# STM32N645 register map
File version: 1.0
CPU: CM55 r0p1, little endian, no MPU, FPU, vendor SysTick, 8 interrupt priority bits
Registers are 32-bit, read-write, reset 0x0 unless marked. A register's access mark holds for its fields unless they carry their own. Offsets are from the block's base; [hi:lo] are bit positions; {n}, {i} and the like mark numbered series.

## PWR — Power control
Base 0x46024800
Same registers: PWR_S 0x56024800
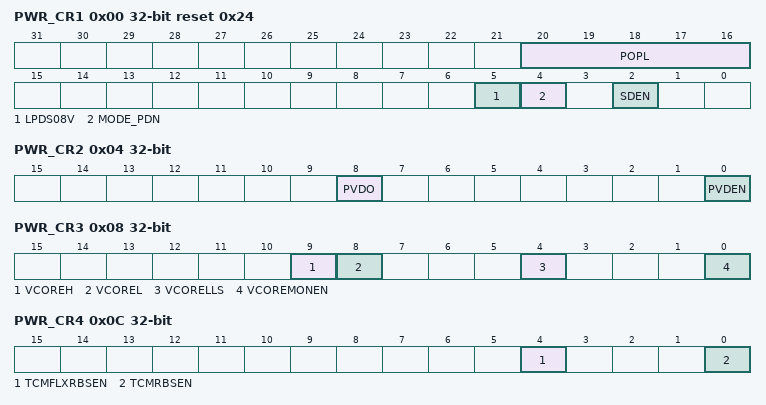
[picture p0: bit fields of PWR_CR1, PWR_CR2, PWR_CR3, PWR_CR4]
0x00 PWR_CR1 access per field reset 0x24 — PWR control register 1
  [20:16] POPL rw — pwr_on pulse low configuration.
    0=No guaranteed minimum low time; 1=~ 1 ms guaranteed minimum low time (1 x 32 LSI cycles); 2=~ 2 ms guaranteed minimum low time (2 x 32 LSI cycles); 31=~ 31 ms guaranteed minimum low time (31 x 32 LSI cycles)
  [5] LPDS08V rw — SMPS low-power mode enable (SVOS high only)
    0=SMPS low-power mode disabled; 1=SMPS low-power mode enabled (high-efficiency mode) (default)
  [4] MODE_PDN rw — Enables the pull down on output voltage during power-down mode
    0=Pull-down disabled. The output is in high impedance during the shutdown (default).; 1=Pull-down enabled
  [2] SDEN rw-once — SMPS step-down converter enable
    0=SMPS step-down converter disabled; 1=SMPS step-down converter enabled (default)
0x04 PWR_CR2 access per field — PWR control register 2
  [8] PVDO ro — Programmable voltage detect output
    0=Voltage level on PVD_IN is equal or higher than the internal VREFINT; 1=Voltage level on PVD_IN is lower than the internal VREFINT
  [0] PVDEN rw — Programmable voltage detector enable
    0=PVD disabled; 1=PVD enabled
0x08 PWR_CR3 access per field — PWR control register 3
  [9] VCOREH ro — Monitored V less than sub>DDCORE less than /sub> level above high threshold
    0=V less than sub>DDCORE less than /sub> level below high threshold level, or monitor disabled; 1=V less than sub>DDCORE less than /sub> level equal or above high threshold level
  [8] VCOREL ro — Monitored V less than sub>DDCORE less than /sub> level above low threshold
    0=V less than sub>DDCORE less than /sub> level above low threshold level, or monitor disabled; 1=V less than sub>DDCORE less than /sub> level equal or below low threshold level
  [4] VCORELLS rw — V less than sub>DDCORE less than /sub> voltage detector low-level selection
    0=V less than sub>DDCORE less than /sub> low-voltage threshold 1 selected (VOS low); 1=V less than sub>DDCORE less than /sub> low-voltage threshold 2 selected (VOS high)
  [0] VCOREMONEN rw — V less than sub>DDCORE less than /sub> monitoring enable
    0=V less than sub>DDCORE less than /sub> monitoring disabled; 1=V less than sub>DDCORE less than /sub> monitoring enabled
0x0C PWR_CR4 — PWR control register 4
  [4] TCMFLXRBSEN — I-TCM FLEXMEM backup supply enable (used to maintain I-TCM FLEX MEM content in Standby mode)
    0=I-TCM FLEXMEM backup supply disabled; 1=I-TCM FLEXMEM backup supply enabled in Standby mode
  [0] TCMRBSEN — I-TCM and D-TCM RAMs backup supply enable (used to maintain TCM RAMs content in Standby mode)
    0=I-TCM and D-TCM RAMs backup supply disabled; 1=I-TCM and D-TCM RAMs backup supply enabled in Standby mode
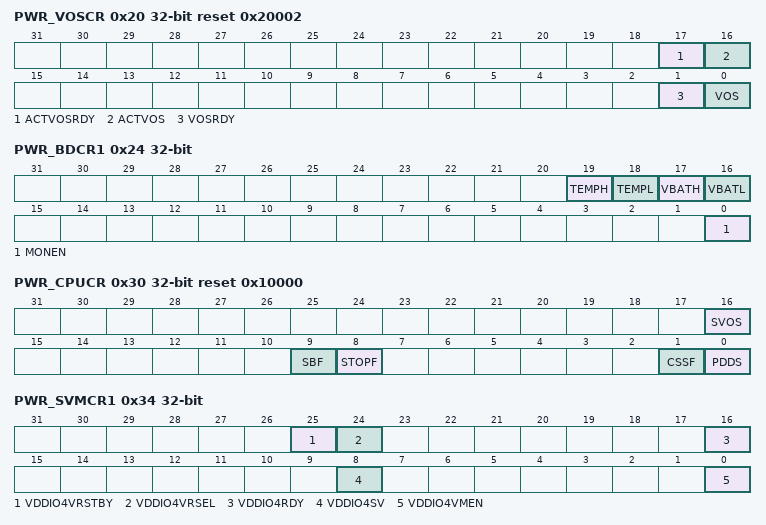
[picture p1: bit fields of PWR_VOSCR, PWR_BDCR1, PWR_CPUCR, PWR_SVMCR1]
0x20 PWR_VOSCR access per field reset 0x20002 — PWR voltage scaling control register
  [17] ACTVOSRDY ro — Voltage level ready bit for currently used ACTVOS
    0=Voltage level invalid, above or below current ACTVOS; 1=Voltage level valid, at current ACTVOS
  [16] ACTVOS ro — VOS currently applied for V less than sub>CORE less than /sub> voltage scaling selection
  [1] VOSRDY ro — VOS ready bit for V less than sub>CORE less than /sub> voltage scaling output selection
    0=Not ready, voltage level below VOS selected level; 1=Ready, voltage level at or above VOS selected level
  [0] VOS rw — Voltage scaling selection according to performance
    0=VOS low level (default); 1=VOS high level
0x24 PWR_BDCR1 access per field — PWR backup domain control register 1
  [19] TEMPH ro — Temperature level monitoring versus high threshold
    0=Temperature below high threshold level; 1=Temperature equal or above high threshold level
  [18] TEMPL ro — Temperature level monitoring versus low threshold
    0=Temperature above low threshold level; 1=Temperature equal or below low threshold level
  [17] VBATH ro — V less than sub>BAT less than /sub> level monitoring versus high threshold
    0=V less than sub>BAT less than /sub> level below high threshold level; 1=V less than sub>BAT less than /sub> level equal or above high threshold level
  [16] VBATL ro — V less than sub>BAT less than /sub> level monitoring versus low threshold
    0=V less than sub>BAT less than /sub> level above low threshold level; 1=V less than sub>BAT less than /sub> level equal or below low threshold level
  [0] MONEN rw — V less than sub>BAT less than /sub> and temperature monitoring enable
    0=V less than sub>BAT less than /sub> and temperature monitoring disabled; 1=V less than sub>BAT less than /sub> and temperature monitoring enabled
0x28 PWR_BDCR2 — PWR backup domain control register 2
  [0] BKPRBSEN — Backup RAM backup supply enable (used to maintain BKPRAM content in Standby and V less than sub>BAT less than /sub> modes).
    0=BKPSRAM backup supply disabled; 1=BKPSRAM backup supply enabled
0x2C PWR_DBPCR — PWR disable backup protection control register
  [0] DBP — Disable backup domain write protection
    0=Write access to backup domain disabled; 1=Write access to backup domain enabled
0x30 PWR_CPUCR access per field reset 0x10000 — PWR CPU control register
  [16] SVOS rw — System Stop mode voltage scaling selection
    0=SVOS low; 1=SVOS high (default)
  [9] SBF ro — Standby flag
    0=System has not been in Standby mode; 1=System has been in Standby mode
  [8] STOPF ro — Stop flag
    0=System has not been in Stop mode; 1=System has been in Stop mode
  [1] CSSF rw — Clear Standby and Stop flags (always read as 0)
    0=No effect; 1=When written, clear the CPU flags (STOPF, SBF)
  [0] PDDS rw — Power-down deepsleep selection
    0=Stop mode when device enters deepsleep; 1=Standby mode when device enters deepsleep
0x34 PWR_SVMCR1 access per field — PWR supply voltage monitoring control register 1
  [25] VDDIO4VRSTBY rw — V less than sub>DDIO4 less than /sub> I/O voltage range Standby mode
    0=VDDIO4VRSEL not retained in Standby mode; 1=VDDIO4VRSEL retained in Standby mode
  [24] VDDIO4VRSEL rw — V less than sub>DDIO4 less than /sub> I/O voltage range selection
    0=3v3 voltage range selected. If V less than sub>DDIO4 less than /sub> is in 1v8 range with this setting, I/Os work in degraded mode.; 1=1v8 voltage range selected. HSLV_VDDIO4 option bit must be set to allow 1v8 voltage range operation. Setting this configuration while V less than sub>DDIO4 less than /sub> is in 3v3 range damages the device.
  [16] VDDIO4RDY ro — V less than sub>DDIO4 less than /sub>ready
    0=V less than sub>DDIO4 less than /sub> is below the threshold of the V less than sub>DDIO4 less than /sub> voltage monitor; 1=V less than sub>DDIO4 less than /sub> is equal or above the threshold of the V less than sub>DDIO4 less than /sub> voltage monitor
  [8] VDDIO4SV rw — V less than sub>DDIO4 less than /sub>independent I/O supply valid.
    0=V less than sub>DDIO4 less than /sub> is not present. Logical and electrical isolation is applied to ignore this supply.; 1=V less than sub>DDIO4 less than /sub> is valid
  [0] VDDIO4VMEN rw — V less than sub>DDIO4 less than /sub>independent I/O voltage monitor enable
    0=V less than sub>DDIO4 less than /sub> voltage monitor disabled; 1=V less than sub>DDIO4 less than /sub> voltage monitor enabled
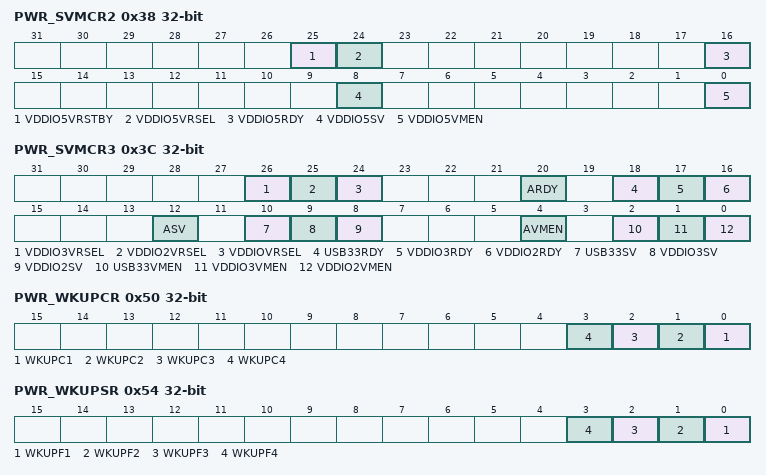
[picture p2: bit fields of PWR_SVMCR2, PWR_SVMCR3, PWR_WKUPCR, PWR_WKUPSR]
0x38 PWR_SVMCR2 access per field — PWR supply voltage monitoring control register 2
  [25] VDDIO5VRSTBY rw — V less than sub>DDIO5 less than /sub> I/O voltage range Standby mode
    0=VDDIO5VRSEL not retained in Standby mode; 1=VDDIO5VRSEL retained in Standby mod
  [24] VDDIO5VRSEL rw — V less than sub>DDIO5 less than /sub> I/O voltage range selection
    0=3v3 voltage range selected. If V less than sub>DDIO5 less than /sub> is in 1v8 range with this setting, I/Os work in degraded mode.; 1=1v8 voltage range selected. HSLV_VDDIO5 option bit must be set to allow 1v8 voltage range operation. Setting this configuration while V less than sub>DDIO5 less than /sub> is in 3v3 range damages the device.
  [16] VDDIO5RDY ro — V less than sub>DDIO5 less than /sub>ready
    0=V less than sub>DDIO5 less than /sub> is below the threshold of the V less than sub>DDIO5 less than /sub> voltage monitor; 1=V less than sub>DDIO5 less than /sub> is equal or above the threshold of the V less than sub>DDIO5 less than /sub> voltage monitor
  [8] VDDIO5SV rw — V less than sub>DDIO5 less than /sub>independent supply valid
    0=V less than sub>DDIO5 less than /sub> is not present. Logical and electrical isolation is applied to ignore this supply.; 1=V less than sub>DDIO5 less than /sub> is valid
  [0] VDDIO5VMEN rw — V less than sub>DDIO5 less than /sub>independent voltage monitor enable
    0=V less than sub>DDIO5 less than /sub>voltage monitor disabled; 1=V less than sub>DDIO5 less than /sub>voltage monitor enabled
0x3C PWR_SVMCR3 access per field — PWR supply voltage monitoring control register 3
  [26] VDDIO3VRSEL rw — V less than sub>DDIO3 less than /sub> I/O voltage range selection
    0=3v3 voltage range selected. If V less than sub>DDIO3 less than /sub> is in 1v8 range with this setting, I/Os work in degraded mode.; 1=1v8 voltage range selected. HSLV_VDDIO3 option bit must be set to allow 1v8 voltage range operation. Setting this configuration while V less than sub>DDIO3 less than /sub> is in 3v3 range damages the device.
  [25] VDDIO2VRSEL rw — V less than sub>DDIO2 less than /sub> I/O voltage range selection
    0=3v3 voltage range selected. If V less than sub>DDIO2 less than /sub> is in 1v8 range with this setting, I/Os work in degraded mode.; 1=1v8 voltage range selected. HSLV_VDDIO2 option bit must be set to allow 1v8 voltage range operation. Setting this configuration while V less than sub>DDIO2 less than /sub> is in 3v3 range damages the device.
  [24] VDDIOVRSEL rw — V less than sub>DD less than /sub> I/O voltage range selection
    0=3v3 voltage range selected. If V less than sub>DD less than /sub> is in 1v8 range with this setting, I/Os work in degraded mode.; 1=1v8 voltage range selected. HSLV_VDD option bit must be set to allow 1v8 voltage range operation. Setting this configuration while V less than sub>DD less than /sub> is in 3v3 range damages the device.
  [20] ARDY ro — V less than sub>DDA18ADC less than /sub>ready
    0=V less than sub>DDA18ADC less than /sub> is below the threshold of the VDDA18ADC voltage monitor; 1=V less than sub>DDA18ADC less than /sub> is equal or above the threshold of the VDDA18ADC voltage monitor
  [18] USB33RDY ro — V less than sub>DD33USB less than /sub>ready
    0=V less than sub>DD33USB less than /sub> is below the threshold of the USB33 voltage monitor; 1=V less than sub>DD33USB less than /sub> is equal or above the threshold of the USB33 voltage monitor
  [17] VDDIO3RDY ro — V less than sub>DDIO3 less than /sub>ready
    0=V less than sub>DDIO3 less than /sub> is below the threshold of the VDDIO3 voltage monitor; 1=V less than sub>DDIO3 less than /sub> is equal or above the threshold of the VDDIO3 voltage monitor
  [16] VDDIO2RDY ro — V less than sub>DDIO2 less than /sub>ready
    0=V less than sub>DDIO2 less than /sub> is below the threshold of the VDDIO2 voltage monitor; 1=V less than sub>DDIO2 less than /sub> is equal or above the threshold of the VDDIO2 voltage monitor
  [12] ASV rw — V less than sub>DDA18ADC less than /sub>independent supply valid
    0=V less than sub>DDA18ADC less than /sub> is not present. Logical and electrical isolation is applied to ignore this supply.; 1=V less than sub>DDA18ADC less than /sub> is valid
  [10] USB33SV rw — V less than sub>DD33USB less than /sub>independent supply valid
    0=V less than sub>DD33USB less than /sub> is not present. Logical and electrical isolation is applied to ignore this supply.; 1=V less than sub>DD33USB less than /sub> is valid
  [9] VDDIO3SV rw — V less than sub>DDIO3 less than /sub>independent supply valid
    0=V less than sub>DDIO3 less than /sub> is not present. Logical and electrical isolation is applied to ignore this supply.; 1=V less than sub>DDIO3 less than /sub> is valid
  [8] VDDIO2SV rw — V less than sub>DDIO2 less than /sub>independent supply valid.
    0=V less than sub>DDIO2 less than /sub> is not present. Logical and electrical isolation is applied to ignore this supply.; 1=V less than sub>DDIO2 less than /sub> is valid
  [4] AVMEN rw — V less than sub>DDA18ADC less than /sub>independent ADC voltage monitor enable
    0=V less than sub>DDA18ADC less than /sub> voltage monitor disabled; 1=V less than sub>DDA18ADC less than /sub> voltage monitor enabled
  [2] USB33VMEN rw — V less than sub>DD33USB less than /sub>independent USB 33 voltage monitor enable.
    0=V less than sub>DD33USB less than /sub> voltage monitor disabled; 1=V less than sub>DD33USB less than /sub> voltage monitor enabled
  [1] VDDIO3VMEN rw — V less than sub>DDIO3 less than /sub>independent voltage monitor enable
    0=V less than sub>DDIO3 less than /sub> voltage monitor disabled; 1=V less than sub>DDIO3 less than /sub> voltage monitor enabled
  [0] VDDIO2VMEN rw — V less than sub>DDIO2 less than /sub>independent voltage monitor enable
    0=V less than sub>DDIO2 less than /sub> voltage monitor disabled; 1=V less than sub>DDIO2 less than /sub> voltage monitor enabled
0x50 PWR_WKUPCR wo — PWR wake-up clear register
  [n-1] WKUPC{n} (n=1..4) — Clear wake-up flag for WKUP{n} pin
    0=No effect; 1=Writing 1 clears WKUPF{n} in PWR_WKUPSR
0x54 PWR_WKUPSR ro — PWR wake-up status register
  [n-1] WKUPF{n} (n=1..4) — Wake-up flag for WKUP{n} pin before enable
    0=No wake-up event occurred; 1=A wake-up event was received from WKUP{n} pin
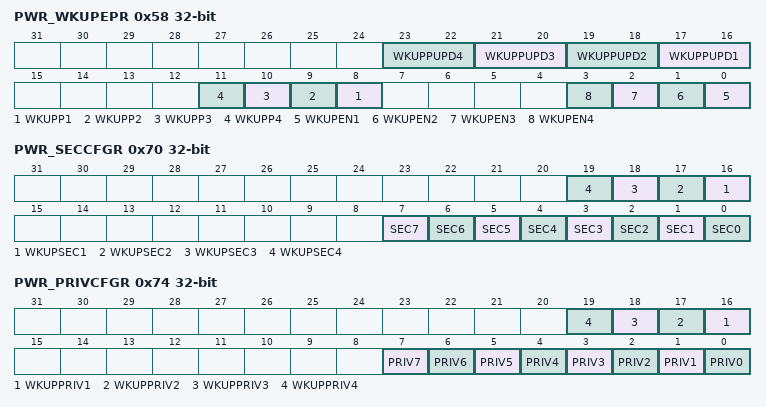
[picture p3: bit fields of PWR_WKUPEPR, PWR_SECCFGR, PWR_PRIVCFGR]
0x58 PWR_WKUPEPR — PWR wake-up enable and polarity register
  [2n+15:2n+14] WKUPPUPD{n} (n=1..4) — Wake-up pull configuration for WKUP{n} pin
    0=No pulls; 1=Pull-up; 2=Pull-down
  [n+7] WKUPP{n} (n=1..4) — Wake-up polarity bit for WKUP{n} pin
    0=Detection on high level (rising edge); 1=Detection on low level (falling edge)
  [n-1] WKUPEN{n} (n=1..4) — Enable WKUP{n} pin
    0=An event on WKUP{n} pin does not wake up the system from Standby and Stop modes; 1=A rising or falling edge on WKUP{n} pin wakes up the system from Standby and Stop modes
0x70 PWR_SECCFGR — PWR security configuration register
  [n+15] WKUPSEC{n} (n=1..4) — WKUP{n} pin secure protection
    0=Bits related to WKUP{n} pin in PWR_WKUPCR, PWR_WKUPSR, and PWR_WKUPEPR can be read and written with secure or non-secure access; 1=Bits related to WKUP{n} pin in PWR_WKUPCR, PWR_WKUPSR, and PWR_WKUPEPR can be read and written only with secure access
  [7] SEC7 — Peripheral voltage monitor secure protection
    0=PWR_SVMCR1, PWR_SVMCR2, and PWR_SVMCR3 can be read and written with secure or non-secure access; 1=PWR_SVMCR1, PWR_SVMCR2, and PWR_SVMCR3 can be read and written only with secure access
  [6] SEC6 — CPU power control secure protection
    0=PWR_CPUCR can be read and written with secure or non-secure access; 1=PWR_CPUCR can be read and written only with secure access
  [5] SEC5 — Backup domain secure protection
    0=PWR_BDCR1, PWR_BDCR2, and PWR_DBPCR can be read and written with secure or non-secure access; 1=PWR_BDCR1, PWR_BDCR2, and PWR_DBPCR can be read and written only with secure access
  [4] SEC4 — Voltage scaling selection secure protection
    0=PWR_VOSCR can be read and written with secure or non-secure access; 1=PWR_VOSCR can be read and written only with secure access
  [3] SEC3 — I-TCM, D-TCM, and I-TCM FLEXMEM low power control secure protection
    0=PWR_CR4 can be read and written with secure or non-secure access; 1=PWR_CR4 can be read and written only with secure access
  [2] SEC2 — V less than sub>DDCORE less than /sub> monitor secure protection
    0=PWR_CR3 can be read and written with secure or non-secure access; 1=PWR_CR3 can be read and written only with secure access
  [1] SEC1 — Programmable voltage detector secure protection
    0=PWR_CR2 can be read and written with secure or non-secure access; 1=PWR_CR2 can be read and written only with secure access
  [0] SEC0 — System supply configuration secure protection
    0=PWR_CR1 can be read and written with secure or non-secure access; 1=PWR_CR1 can be read and written only with secure access
0x74 PWR_PRIVCFGR — PWR privilege configuration register
  [n+15] WKUPPRIV{n} (n=1..4) — WKUP{n} pin privileged protection
    0=Bits related to WKUP{n} pin in PWR_WKUPCR, PWR_WKUPSR, and PWR_WKUPEPR can be read and written with privileged or unprivileged access; 1=Bits related to WKUP{n} pin in PWR_WKUPCR, PWR_WKUPSR, and PWR_WKUPEPR can be read and written only with privileged access
  [7] PRIV7 — Peripheral voltage monitor privileged protection
    0=PWR_SVMCR1, PWR_SVMCR2, and PWR_SVMCR3 can be read and written with privileged or unprivileged access; 1=PWR_SVMCR1, PWR_SVMCR2, and PWR_SVMCR3 can be read and written only with privileged access
  [6] PRIV6 — CPU power control privileged protection
    0=PWR_CPUCR can be read and written with privileged or unprivileged access; 1=PWR_CPUCR can be read and written only with privileged access
  [5] PRIV5 — Backup domain privileged protection
    0=PWR_BDCR1, PWR_BDCR2, and PWR_DBPCR can be read and written with privileged or unprivileged access; 1=PWR_BDCR1, PWR_BDCR2, and PWR_DBPCR can be read and written only with privileged access
  [4] PRIV4 — Voltage scaling selection privileged protection
    0=PWR_VOSCR can be read and written with privileged or unprivileged access; 1=PWR_VOSCR can be read and written only with privileged access
  [3] PRIV3 — I-TCM, D-TCM, and I-TCM FLEX MEM low power control privileged protection
    0=PWR_CR4 can be read and written with privileged or unprivileged access; 1=PWR_CR4 can be read and written only with privileged access
  [2] PRIV2 — V less than sub>DDCORE less than /sub> monitor privileged protection
    0=PWR_CR3 can be read and written with privileged or unprivileged access; 1=PWR_CR3 can be read and written only with privileged access
  [1] PRIV1 — Programmable voltage detector privileged protection
    0=PWR_CR2 can be read and written with privileged or unprivileged access; 1=PWR_CR2 can be read and written only with privileged access
  [0] PRIV0 — System supply configuration privileged protection
    0=PWR_CR1 can be read and written with privileged or unprivileged access; 1=PWR_CR1 can be read and written only with privileged access
